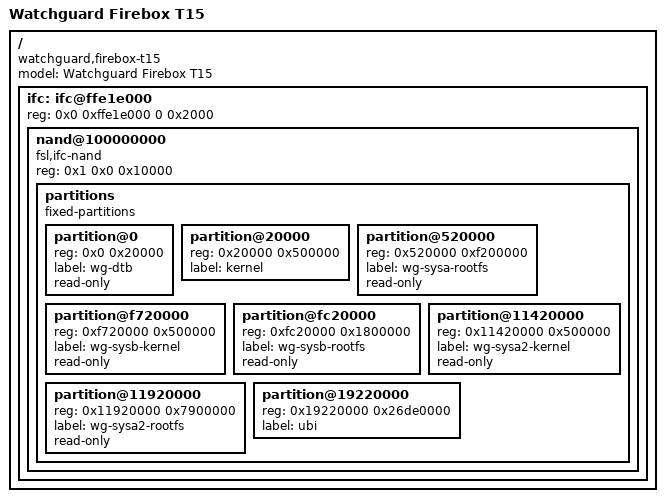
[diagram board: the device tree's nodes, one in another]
// SPDX-License-Identifier: GPL-2.0-or-later or MIT

/include/ "fsl/p1010si-pre.dtsi"
#include "firebox-t1x.dtsi"

/ {
	model = "Watchguard Firebox T15";
	compatible = "watchguard,firebox-t15";

	ifc: ifc@ffe1e000 {
		reg = <0x0 0xffe1e000 0 0x2000>;

		/* NOR, NAND Flashes and CPLD on board */
		ranges = <0x0 0x0 0x0 0xee000000 0x02000000>,
			 <0x1 0x0 0x0 0xff800000 0x00010000>,
			 <0x3 0x0 0x0 0xffb00000 0x00000020>;

		nand@100000000 {
			compatible = "fsl,ifc-nand";
			reg = <0x1 0x0 0x10000>;

			partitions {
				compatible = "fixed-partitions";
				#address-cells = <1>;
				#size-cells = <1>;

				/*
				 * Original partition layout:
				 * 0x000000000000-0x000000020000 : "NAND (RW) WG DTB Image"
				 * 0x000000020000-0x000000520000 : "NAND (RW) WG SYSA Kernel"
				 * 0x000000520000-0x00000f720000 : "NAND (RW) WG SYSA_CODE"
				 * 0x00000f720000-0x00000fc20000 : "NAND (RW) WG SYSB Kernel"
				 * 0x00000fc20000-0x000011420000 : "NAND (RW) WG SYSB_CODE"
				 * 0x000011420000-0x000011920000 : "NAND (RW) WG SYSA2 Kernel"
				 * 0x000011920000-0x000019220000 : "NAND (RW) WG SYSA_CODE2"
				 * 0x000019220000-0x000040000000 : "NAND (RW) WG SYSA_DATA"
				 */

				partition@0 {
					reg = <0x0 0x20000>;
					label = "wg-dtb";
					read-only;
				};

				partition@20000 {
					reg = <0x20000 0x500000>;
					label = "kernel";
				};

				partition@520000 {
					reg = <0x520000 0xf200000>;
					label = "wg-sysa-rootfs";
					read-only;
				};

				partition@f720000 {
					reg = <0xf720000 0x500000>;
					label = "wg-sysb-kernel";
					read-only;
				};

				partition@fc20000 {
					reg = <0xfc20000 0x1800000>;
					label = "wg-sysb-rootfs";
					read-only;
				};

				partition@11420000 {
					reg = <0x11420000 0x500000>;
					label = "wg-sysa2-kernel";
					read-only;
				};

				partition@11920000 {
					reg = <0x11920000 0x7900000>;
					label = "wg-sysa2-rootfs";
					read-only;
				};

				partition@19220000 {
					reg = <0x19220000 0x26de0000>;
					label = "ubi";
				};
			};
		};
	};
};

/include/ "fsl/p1010si-post.dtsi"
